AUTOSAR XML (schema 00044)
package /ComponentTypes
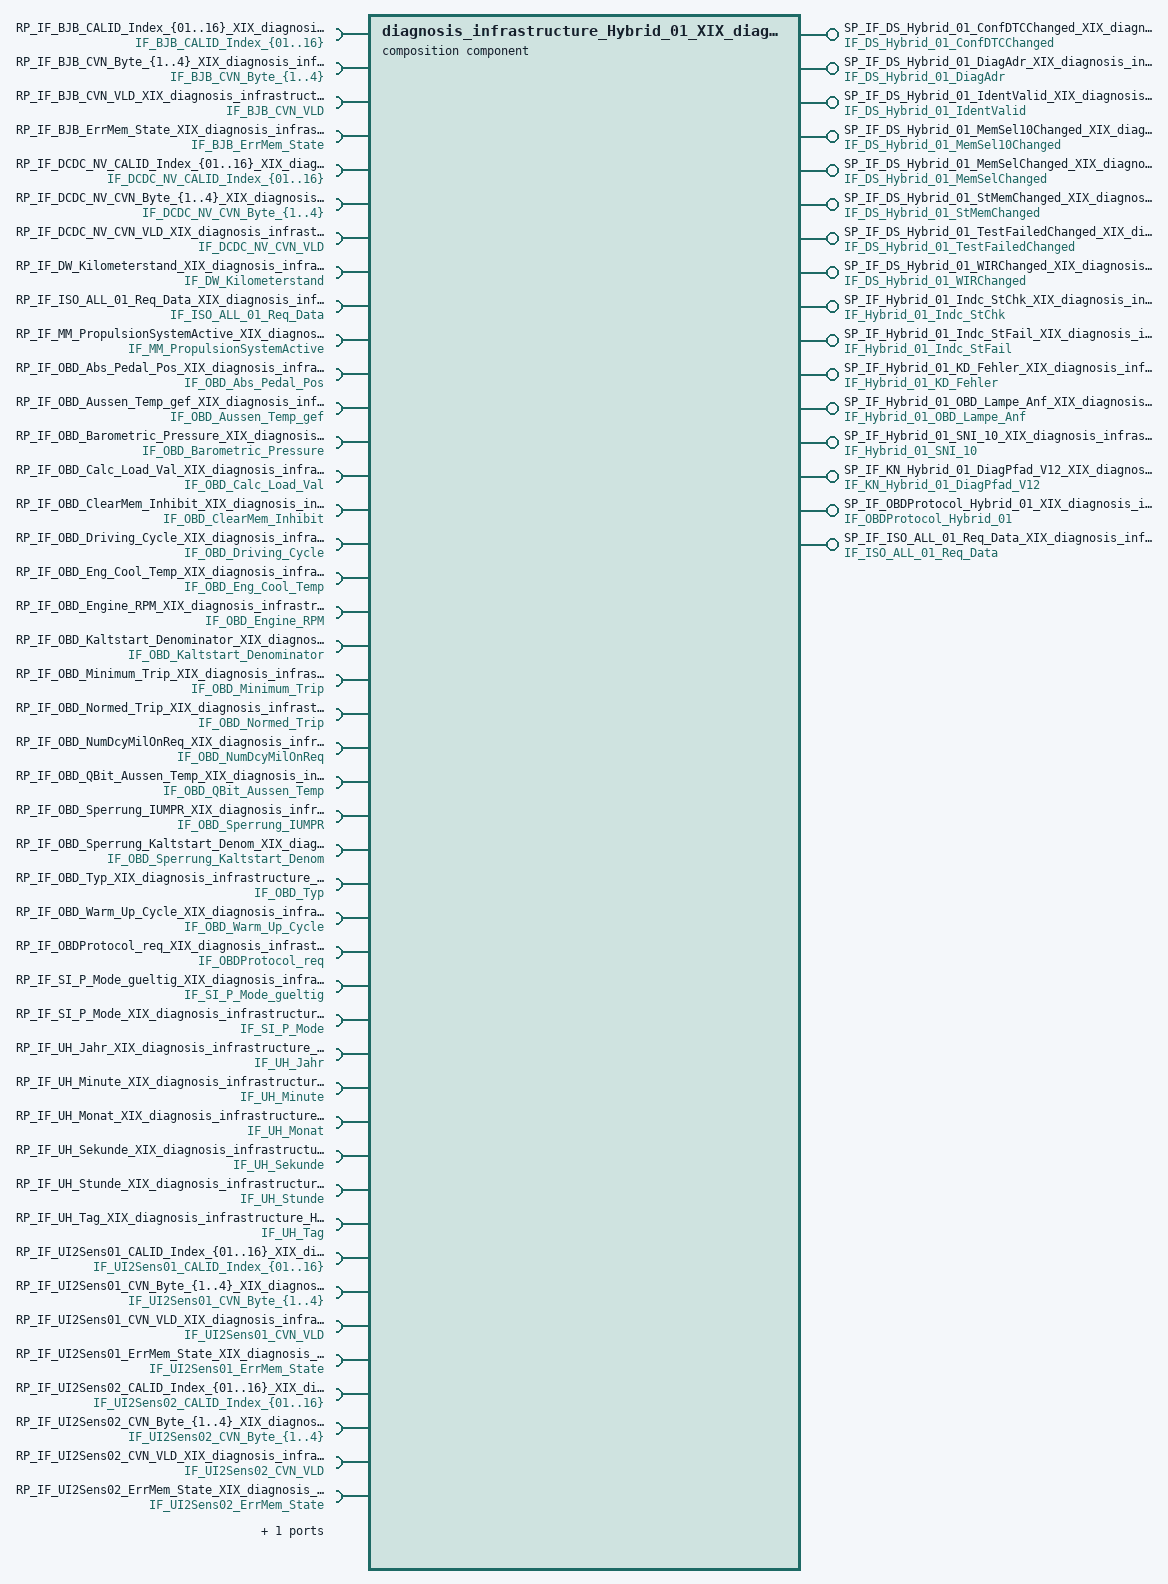
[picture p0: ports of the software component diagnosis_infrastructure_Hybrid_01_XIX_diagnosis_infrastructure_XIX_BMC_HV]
  composition sw component type diagnosis_infrastructure_Hybrid_01_XIX_diagnosis_infrastructure_XIX_BMC_HV
    15 x provide port:
      SP_IF_DS_Hybrid_01_ConfDTCChanged_XIX_diagnosis_infrastructure_Hybrid_01_XIX_diagnosis_infrastructure_XIX_BMC_HV: nonqueued-sender-com-spec=DE_DS_Hybrid_01_ConfDTCChanged, provided-interface=IF_DS_Hybrid_01_ConfDTCChanged
      SP_IF_DS_Hybrid_01_DiagAdr_XIX_diagnosis_infrastructure_Hybrid_01_XIX_diagnosis_infrastructure_XIX_BMC_HV: nonqueued-sender-com-spec=DE_DS_Hybrid_01_DiagAdr, provided-interface=IF_DS_Hybrid_01_DiagAdr
      SP_IF_DS_Hybrid_01_IdentValid_XIX_diagnosis_infrastructure_Hybrid_01_XIX_diagnosis_infrastructure_XIX_BMC_HV: nonqueued-sender-com-spec=DE_DS_Hybrid_01_IdentValid, provided-interface=IF_DS_Hybrid_01_IdentValid
      SP_IF_DS_Hybrid_01_MemSel10Changed_XIX_diagnosis_infrastructure_Hybrid_01_XIX_diagnosis_infrastructure_XIX_BMC_HV: nonqueued-sender-com-spec=DE_DS_Hybrid_01_MemSel10Changed, provided-interface=IF_DS_Hybrid_01_MemSel10Changed
      SP_IF_DS_Hybrid_01_MemSelChanged_XIX_diagnosis_infrastructure_Hybrid_01_XIX_diagnosis_infrastructure_XIX_BMC_HV: nonqueued-sender-com-spec=DE_DS_Hybrid_01_MemSelChanged, provided-interface=IF_DS_Hybrid_01_MemSelChanged
      SP_IF_DS_Hybrid_01_StMemChanged_XIX_diagnosis_infrastructure_Hybrid_01_XIX_diagnosis_infrastructure_XIX_BMC_HV: nonqueued-sender-com-spec=DE_DS_Hybrid_01_StMemChanged, provided-interface=IF_DS_Hybrid_01_StMemChanged
      SP_IF_DS_Hybrid_01_TestFailedChanged_XIX_diagnosis_infrastructure_Hybrid_01_XIX_diagnosis_infrastructure_XIX_BMC_HV: nonqueued-sender-com-spec=DE_DS_Hybrid_01_TestFailedChanged, provided-interface=IF_DS_Hybrid_01_TestFailedChanged
      SP_IF_DS_Hybrid_01_WIRChanged_XIX_diagnosis_infrastructure_Hybrid_01_XIX_diagnosis_infrastructure_XIX_BMC_HV: nonqueued-sender-com-spec=DE_DS_Hybrid_01_WIRChanged, provided-interface=IF_DS_Hybrid_01_WIRChanged
      SP_IF_Hybrid_01_Indc_StChk_XIX_diagnosis_infrastructure_Hybrid_01_XIX_diagnosis_infrastructure_XIX_BMC_HV: nonqueued-sender-com-spec=DE_Hybrid_01_Indc_StChk, provided-interface=IF_Hybrid_01_Indc_StChk
      SP_IF_Hybrid_01_Indc_StFail_XIX_diagnosis_infrastructure_Hybrid_01_XIX_diagnosis_infrastructure_XIX_BMC_HV: nonqueued-sender-com-spec=DE_Hybrid_01_Indc_StFail, provided-interface=IF_Hybrid_01_Indc_StFail
      SP_IF_Hybrid_01_KD_Fehler_XIX_diagnosis_infrastructure_Hybrid_01_XIX_diagnosis_infrastructure_XIX_BMC_HV: nonqueued-sender-com-spec=DE_Hybrid_01_KD_Fehler, provided-interface=IF_Hybrid_01_KD_Fehler
      SP_IF_Hybrid_01_OBD_Lampe_Anf_XIX_diagnosis_infrastructure_Hybrid_01_XIX_diagnosis_infrastructure_XIX_BMC_HV: nonqueued-sender-com-spec=DE_Hybrid_01_OBD_Lampe_Anf, provided-interface=IF_Hybrid_01_OBD_Lampe_Anf
      SP_IF_Hybrid_01_SNI_10_XIX_diagnosis_infrastructure_Hybrid_01_XIX_diagnosis_infrastructure_XIX_BMC_HV: nonqueued-sender-com-spec=DE_Hybrid_01_SNI_10, provided-interface=IF_Hybrid_01_SNI_10
      SP_IF_KN_Hybrid_01_DiagPfad_V12_XIX_diagnosis_infrastructure_Hybrid_01_XIX_diagnosis_infrastructure_XIX_BMC_HV: nonqueued-sender-com-spec=DE_KN_Hybrid_01_DiagPfad_V12, provided-interface=IF_KN_Hybrid_01_DiagPfad_V12
      SP_IF_OBDProtocol_Hybrid_01_XIX_diagnosis_infrastructure_Hybrid_01_XIX_diagnosis_infrastructure_XIX_BMC_HV: nonqueued-sender-com-spec=DE_OBDProtocol_Hybrid_01, provided-interface=IF_OBDProtocol_Hybrid_01
    117 x require port:
      RP_IF_BJB_CALID_Index_{01..16}_XIX_diagnosis_infrastructure_Hybrid_01_XIX_diagnosis_infrastructure_XIX_BMC_HV: nonqueued-receiver-com-spec=DE_BJB_CALID_Index_{01..16}, required-interface=IF_BJB_CALID_Index_{01..16}
      RP_IF_BJB_CVN_Byte_{1..4}_XIX_diagnosis_infrastructure_Hybrid_01_XIX_diagnosis_infrastructure_XIX_BMC_HV: nonqueued-receiver-com-spec=DE_BJB_CVN_Byte_{1..4}, required-interface=IF_BJB_CVN_Byte_{1..4}
      RP_IF_BJB_CVN_VLD_XIX_diagnosis_infrastructure_Hybrid_01_XIX_diagnosis_infrastructure_XIX_BMC_HV: nonqueued-receiver-com-spec=DE_BJB_CVN_VLD, required-interface=IF_BJB_CVN_VLD
      RP_IF_BJB_ErrMem_State_XIX_diagnosis_infrastructure_Hybrid_01_XIX_diagnosis_infrastructure_XIX_BMC_HV: nonqueued-receiver-com-spec=DE_BJB_ErrMem_State, required-interface=IF_BJB_ErrMem_State
      RP_IF_DCDC_NV_CALID_Index_{01..16}_XIX_diagnosis_infrastructure_Hybrid_01_XIX_diagnosis_infrastructure_XIX_BMC_HV: nonqueued-receiver-com-spec=DE_DCDC_NV_CALID_Index_{01..16}, required-interface=IF_DCDC_NV_CALID_Index_{01..16}
      RP_IF_DCDC_NV_CVN_Byte_{1..4}_XIX_diagnosis_infrastructure_Hybrid_01_XIX_diagnosis_infrastructure_XIX_BMC_HV: nonqueued-receiver-com-spec=DE_DCDC_NV_CVN_Byte_{1..4}, required-interface=IF_DCDC_NV_CVN_Byte_{1..4}
      RP_IF_DCDC_NV_CVN_VLD_XIX_diagnosis_infrastructure_Hybrid_01_XIX_diagnosis_infrastructure_XIX_BMC_HV: nonqueued-receiver-com-spec=DE_DCDC_NV_CVN_VLD, required-interface=IF_DCDC_NV_CVN_VLD
      RP_IF_DW_Kilometerstand_XIX_diagnosis_infrastructure_Hybrid_01_XIX_diagnosis_infrastructure_XIX_BMC_HV: nonqueued-receiver-com-spec=DE_DW_Kilometerstand, required-interface=IF_DW_Kilometerstand
      RP_IF_ISO_ALL_01_Req_Data_XIX_diagnosis_infrastructure_Hybrid_01_XIX_diagnosis_infrastructure_XIX_BMC_HV: nonqueued-receiver-com-spec=DE_ISO_ALL_01_Req_Data, required-interface=IF_ISO_ALL_01_Req_Data
      RP_IF_MM_PropulsionSystemActive_XIX_diagnosis_infrastructure_Hybrid_01_XIX_diagnosis_infrastructure_XIX_BMC_HV: nonqueued-receiver-com-spec=DE_MM_PropulsionSystemActive, required-interface=IF_MM_PropulsionSystemActive
      RP_IF_OBD_Abs_Pedal_Pos_XIX_diagnosis_infrastructure_Hybrid_01_XIX_diagnosis_infrastructure_XIX_BMC_HV: nonqueued-receiver-com-spec=DE_OBD_Abs_Pedal_Pos, required-interface=IF_OBD_Abs_Pedal_Pos
      RP_IF_OBD_Aussen_Temp_gef_XIX_diagnosis_infrastructure_Hybrid_01_XIX_diagnosis_infrastructure_XIX_BMC_HV: nonqueued-receiver-com-spec=DE_OBD_Aussen_Temp_gef, required-interface=IF_OBD_Aussen_Temp_gef
      RP_IF_OBD_Barometric_Pressure_XIX_diagnosis_infrastructure_Hybrid_01_XIX_diagnosis_infrastructure_XIX_BMC_HV: nonqueued-receiver-com-spec=DE_OBD_Barometric_Pressure, required-interface=IF_OBD_Barometric_Pressure
      RP_IF_OBD_Calc_Load_Val_XIX_diagnosis_infrastructure_Hybrid_01_XIX_diagnosis_infrastructure_XIX_BMC_HV: nonqueued-receiver-com-spec=DE_OBD_Calc_Load_Val, required-interface=IF_OBD_Calc_Load_Val
      RP_IF_OBD_ClearMem_Inhibit_XIX_diagnosis_infrastructure_Hybrid_01_XIX_diagnosis_infrastructure_XIX_BMC_HV: nonqueued-receiver-com-spec=DE_OBD_ClearMem_Inhibit, required-interface=IF_OBD_ClearMem_Inhibit
      RP_IF_OBD_Driving_Cycle_XIX_diagnosis_infrastructure_Hybrid_01_XIX_diagnosis_infrastructure_XIX_BMC_HV: nonqueued-receiver-com-spec=DE_OBD_Driving_Cycle, required-interface=IF_OBD_Driving_Cycle
      RP_IF_OBD_Eng_Cool_Temp_XIX_diagnosis_infrastructure_Hybrid_01_XIX_diagnosis_infrastructure_XIX_BMC_HV: nonqueued-receiver-com-spec=DE_OBD_Eng_Cool_Temp, required-interface=IF_OBD_Eng_Cool_Temp
      RP_IF_OBD_Engine_RPM_XIX_diagnosis_infrastructure_Hybrid_01_XIX_diagnosis_infrastructure_XIX_BMC_HV: nonqueued-receiver-com-spec=DE_OBD_Engine_RPM, required-interface=IF_OBD_Engine_RPM
      RP_IF_OBD_Kaltstart_Denominator_XIX_diagnosis_infrastructure_Hybrid_01_XIX_diagnosis_infrastructure_XIX_BMC_HV: nonqueued-receiver-com-spec=DE_OBD_Kaltstart_Denominator, required-interface=IF_OBD_Kaltstart_Denominator
      RP_IF_OBD_Minimum_Trip_XIX_diagnosis_infrastructure_Hybrid_01_XIX_diagnosis_infrastructure_XIX_BMC_HV: nonqueued-receiver-com-spec=DE_OBD_Minimum_Trip, required-interface=IF_OBD_Minimum_Trip
      RP_IF_OBD_Normed_Trip_XIX_diagnosis_infrastructure_Hybrid_01_XIX_diagnosis_infrastructure_XIX_BMC_HV: nonqueued-receiver-com-spec=DE_OBD_Normed_Trip, required-interface=IF_OBD_Normed_Trip
      RP_IF_OBD_NumDcyMilOnReq_XIX_diagnosis_infrastructure_Hybrid_01_XIX_diagnosis_infrastructure_XIX_BMC_HV: nonqueued-receiver-com-spec=DE_OBD_NumDcyMilOnReq, required-interface=IF_OBD_NumDcyMilOnReq
      RP_IF_OBD_QBit_Aussen_Temp_XIX_diagnosis_infrastructure_Hybrid_01_XIX_diagnosis_infrastructure_XIX_BMC_HV: nonqueued-receiver-com-spec=DE_OBD_QBit_Aussen_Temp, required-interface=IF_OBD_QBit_Aussen_Temp
      RP_IF_OBD_Sperrung_IUMPR_XIX_diagnosis_infrastructure_Hybrid_01_XIX_diagnosis_infrastructure_XIX_BMC_HV: nonqueued-receiver-com-spec=DE_OBD_Sperrung_IUMPR, required-interface=IF_OBD_Sperrung_IUMPR
      RP_IF_OBD_Sperrung_Kaltstart_Denom_XIX_diagnosis_infrastructure_Hybrid_01_XIX_diagnosis_infrastructure_XIX_BMC_HV: nonqueued-receiver-com-spec=DE_OBD_Sperrung_Kaltstart_Denom, required-interface=IF_OBD_Sperrung_Kaltstart_Denom
      RP_IF_OBD_Typ_XIX_diagnosis_infrastructure_Hybrid_01_XIX_diagnosis_infrastructure_XIX_BMC_HV: nonqueued-receiver-com-spec=DE_OBD_Typ, required-interface=IF_OBD_Typ
      RP_IF_OBD_Warm_Up_Cycle_XIX_diagnosis_infrastructure_Hybrid_01_XIX_diagnosis_infrastructure_XIX_BMC_HV: nonqueued-receiver-com-spec=DE_OBD_Warm_Up_Cycle, required-interface=IF_OBD_Warm_Up_Cycle
      RP_IF_OBDProtocol_req_XIX_diagnosis_infrastructure_Hybrid_01_XIX_diagnosis_infrastructure_XIX_BMC_HV: nonqueued-receiver-com-spec=DE_OBDProtocol_req, required-interface=IF_OBDProtocol_req
      RP_IF_SI_P_Mode_gueltig_XIX_diagnosis_infrastructure_Hybrid_01_XIX_diagnosis_infrastructure_XIX_BMC_HV: nonqueued-receiver-com-spec=DE_SI_P_Mode_gueltig, required-interface=IF_SI_P_Mode_gueltig
      RP_IF_SI_P_Mode_XIX_diagnosis_infrastructure_Hybrid_01_XIX_diagnosis_infrastructure_XIX_BMC_HV: nonqueued-receiver-com-spec=DE_SI_P_Mode, required-interface=IF_SI_P_Mode
      RP_IF_UH_Jahr_XIX_diagnosis_infrastructure_Hybrid_01_XIX_diagnosis_infrastructure_XIX_BMC_HV: nonqueued-receiver-com-spec=DE_UH_Jahr, required-interface=IF_UH_Jahr
      RP_IF_UH_Minute_XIX_diagnosis_infrastructure_Hybrid_01_XIX_diagnosis_infrastructure_XIX_BMC_HV: nonqueued-receiver-com-spec=DE_UH_Minute, required-interface=IF_UH_Minute
      RP_IF_UH_Monat_XIX_diagnosis_infrastructure_Hybrid_01_XIX_diagnosis_infrastructure_XIX_BMC_HV: nonqueued-receiver-com-spec=DE_UH_Monat, required-interface=IF_UH_Monat
      RP_IF_UH_Sekunde_XIX_diagnosis_infrastructure_Hybrid_01_XIX_diagnosis_infrastructure_XIX_BMC_HV: nonqueued-receiver-com-spec=DE_UH_Sekunde, required-interface=IF_UH_Sekunde
      RP_IF_UH_Stunde_XIX_diagnosis_infrastructure_Hybrid_01_XIX_diagnosis_infrastructure_XIX_BMC_HV: nonqueued-receiver-com-spec=DE_UH_Stunde, required-interface=IF_UH_Stunde
      RP_IF_UH_Tag_XIX_diagnosis_infrastructure_Hybrid_01_XIX_diagnosis_infrastructure_XIX_BMC_HV: nonqueued-receiver-com-spec=DE_UH_Tag, required-interface=IF_UH_Tag
      RP_IF_UI2Sens01_CALID_Index_{01..16}_XIX_diagnosis_infrastructure_Hybrid_01_XIX_diagnosis_infrastructure_XIX_BMC_HV: nonqueued-receiver-com-spec=DE_UI2Sens01_CALID_Index_{01..16}, required-interface=IF_UI2Sens01_CALID_Index_{01..16}
      RP_IF_UI2Sens01_CVN_Byte_{1..4}_XIX_diagnosis_infrastructure_Hybrid_01_XIX_diagnosis_infrastructure_XIX_BMC_HV: nonqueued-receiver-com-spec=DE_UI2Sens01_CVN_Byte_{1..4}, required-interface=IF_UI2Sens01_CVN_Byte_{1..4}
      RP_IF_UI2Sens01_CVN_VLD_XIX_diagnosis_infrastructure_Hybrid_01_XIX_diagnosis_infrastructure_XIX_BMC_HV: nonqueued-receiver-com-spec=DE_UI2Sens01_CVN_VLD, required-interface=IF_UI2Sens01_CVN_VLD
      RP_IF_UI2Sens01_ErrMem_State_XIX_diagnosis_infrastructure_Hybrid_01_XIX_diagnosis_infrastructure_XIX_BMC_HV: nonqueued-receiver-com-spec=DE_UI2Sens01_ErrMem_State, required-interface=IF_UI2Sens01_ErrMem_State
      RP_IF_UI2Sens02_CALID_Index_{01..16}_XIX_diagnosis_infrastructure_Hybrid_01_XIX_diagnosis_infrastructure_XIX_BMC_HV: nonqueued-receiver-com-spec=DE_UI2Sens02_CALID_Index_{01..16}, required-interface=IF_UI2Sens02_CALID_Index_{01..16}
      RP_IF_UI2Sens02_CVN_Byte_{1..4}_XIX_diagnosis_infrastructure_Hybrid_01_XIX_diagnosis_infrastructure_XIX_BMC_HV: nonqueued-receiver-com-spec=DE_UI2Sens02_CVN_Byte_{1..4}, required-interface=IF_UI2Sens02_CVN_Byte_{1..4}
      RP_IF_UI2Sens02_CVN_VLD_XIX_diagnosis_infrastructure_Hybrid_01_XIX_diagnosis_infrastructure_XIX_BMC_HV: nonqueued-receiver-com-spec=DE_UI2Sens02_CVN_VLD, required-interface=IF_UI2Sens02_CVN_VLD
      RP_IF_UI2Sens02_ErrMem_State_XIX_diagnosis_infrastructure_Hybrid_01_XIX_diagnosis_infrastructure_XIX_BMC_HV: nonqueued-receiver-com-spec=DE_UI2Sens02_ErrMem_State, required-interface=IF_UI2Sens02_ErrMem_State
      RP_IF_VDSO_Vx3d_XIX_diagnosis_infrastructure_Hybrid_01_XIX_diagnosis_infrastructure_XIX_BMC_HV: nonqueued-receiver-com-spec=DE_VDSO_Vx3d, required-interface=IF_VDSO_Vx3d
    provide port SP_IF_ISO_ALL_01_Req_Data_XIX_diagnosis_infrastructure_Hybrid_01_XIX_diagnosis_infrastructure_XIX_BMC_HV: nonqueued-sender-com-spec=DE_ISO_ALL_01_Req_Data, provided-interface=IF_ISO_ALL_01_Req_Data
